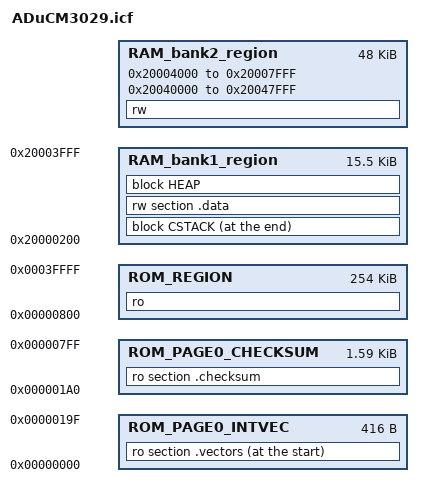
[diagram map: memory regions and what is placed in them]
/******************************************************************************
*  File: ADuCM3029.icf
*  ILINK Configuration File for Analog Devices ADuCM3029 processor
*
*  Copyright (c) 2011 - 2014 ARM LIMITED
*  Copyright (c) 2016 - 2017 Analog Devices, Inc.
*
*  All rights reserved.
*  Redistribution and use in source and binary forms, with or without
*  modification, are permitted provided that the following conditions are met:
*  - Redistributions of source code must retain the above copyright
*    notice, this list of conditions and the following disclaimer.
*  - Redistributions in binary form must reproduce the above copyright
*    notice, this list of conditions and the following disclaimer in the
*    documentation and/or other materials provided with the distribution.
*  - Neither the name of ARM nor the names of its contributors may be used
*    to endorse or promote products derived from this software without
*    specific prior written permission.
*
*  THIS SOFTWARE IS PROVIDED BY THE COPYRIGHT HOLDERS AND CONTRIBUTORS "AS IS"
*  AND ANY EXPRESS OR IMPLIED WARRANTIES, INCLUDING, BUT NOT LIMITED TO, THE
*  IMPLIED WARRANTIES OF MERCHANTABILITY AND FITNESS FOR A PARTICULAR PURPOSE
*  ARE DISCLAIMED. IN NO EVENT SHALL COPYRIGHT HOLDERS AND CONTRIBUTORS BE
*  LIABLE FOR ANY DIRECT, INDIRECT, INCIDENTAL, SPECIAL, EXEMPLARY, OR
*  CONSEQUENTIAL DAMAGES (INCLUDING, BUT NOT LIMITED TO, PROCUREMENT OF
*  SUBSTITUTE GOODS OR SERVICES; LOSS OF USE, DATA, OR PROFITS; OR BUSINESS
*  INTERRUPTION) HOWEVER CAUSED AND ON ANY THEORY OF LIABILITY, WHETHER IN
*  CONTRACT, STRICT LIABILITY, OR TORT (INCLUDING NEGLIGENCE OR OTHERWISE)
*  ARISING IN ANY WAY OUT OF THE USE OF THIS SOFTWARE, EVEN IF ADVISED OF THE
*  POSSIBILITY OF SUCH DAMAGE.
******************************************************************************/
define memory mem with size               = 4G;
define region ROM_PAGE0_INTVEC            = mem:[from 0x00000000 size 0x000001A0];
define region ROM_PAGE0_CHECKSUM          = mem:[from 0x000001A0 size 0x00000660];
define region ROM_REGION                  = mem:[from 0x00000800 size 254K];
define region RAM_bank1_region            = mem:[from 0x20000200 size 0x00003E00];
define region RAM_bank2_region            = mem:[from 0x20004000 size 0x00004000]
                                          | mem:[from 0x20040000 size 0x00008000];
define block CSTACK   with alignment = 16, size = 0x1000 { };
define block HEAP     with alignment = 16, size = 0x2000 { };
do not initialize                         { section .noinit };
initialize by copy                        { rw };
place at start of ROM_PAGE0_INTVEC        { ro section .vectors };
place in          ROM_PAGE0_CHECKSUM      { ro section .checksum };
place in          ROM_REGION              { ro };
place at end of   RAM_bank1_region        { block CSTACK };
place in          RAM_bank1_region        { rw section .data };
place in          RAM_bank1_region        { block HEAP };
place in          RAM_bank2_region        { rw };
